# MK40D7 register map
File version: 1.6
Registers are 32-bit, read-write, reset 0x0 unless marked. A register's access mark holds for its fields unless they carry their own. Offsets are from the block's base; [hi:lo] are bit positions; {n}, {i} and the like mark numbered series.

## USB0 — Universal Serial Bus, OTG Capable Controller
Base 0x40072000; register names take the prefix USB0_
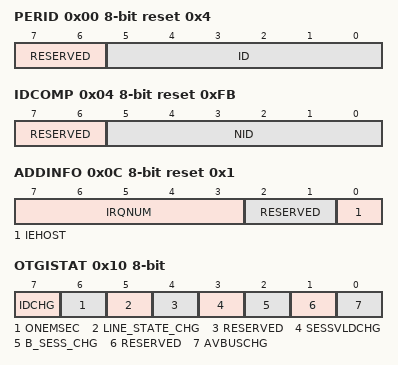
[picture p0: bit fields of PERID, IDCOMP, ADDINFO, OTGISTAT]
0x00 PERID 8-bit ro reset 0x4 — Peripheral ID Register
  [7:6] RESERVED
  [5:0] ID — Peripheral identification bits
0x04 IDCOMP 8-bit ro reset 0xFB — Peripheral ID Complement Register
  [7:6] RESERVED, [5:0] NID
0x08 REV 8-bit ro reset 0x33 — Peripheral Revision Register
  [7:0] REV — Revision
0x0C ADDINFO 8-bit ro reset 0x1 — Peripheral Additional Info Register
  [7:3] IRQNUM — Assigned Interrupt Request Number
  [2:1] RESERVED
  [0] IEHOST
0x10 OTGISTAT 8-bit access per field — OTG Interrupt Status Register
  [7] IDCHG rw, [6] ONEMSEC rw, [5] LINE_STATE_CHG rw, [4] RESERVED ro, [3] SESSVLDCHG rw, [2] B_SESS_CHG rw, [1] RESERVED ro, [0] AVBUSCHG rw
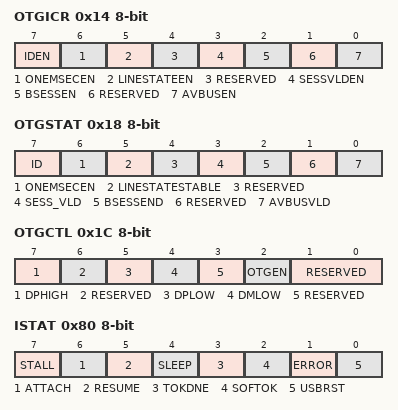
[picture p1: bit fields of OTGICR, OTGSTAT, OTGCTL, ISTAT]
0x14 OTGICR 8-bit access per field — OTG Interrupt Control Register
  [7] IDEN rw — ID interrupt enable
    0=The ID interrupt is disabled; 1=The ID interrupt is enabled
  [6] ONEMSECEN rw — 1 millisecond interrupt enable
    0=The 1msec timer interrupt is disabled; 1=The 1msec timer interrupt is enabled
  [5] LINESTATEEN rw — Line State change interrupt enable
    0=The LINE_STAT_CHG interrupt is disabled; 1=The LINE_STAT_CHG interrupt is enabled
  [4] RESERVED ro
  [3] SESSVLDEN rw — Session valid interrupt enable
    0=The SESSVLDCHG interrupt is disabled; 1=The SESSVLDCHG interrupt is enabled
  [2] BSESSEN rw — B Session END interrupt enable
    0=The B_SESS_CHG interrupt is disabled; 1=The B_SESS_CHG interrupt is enabled
  [1] RESERVED ro
  [0] AVBUSEN rw — A VBUS Valid interrupt enable
    0=The AVBUSCHG interrupt is disabled; 1=The AVBUSCHG interrupt is enabled
0x18 OTGSTAT 8-bit access per field — OTG Status Register
  [7] ID rw
    0=Indicates a Type A cable has been plugged into the USB connector; 1=Indicates no cable is attached or a Type B cable has been plugged into the USB connector
  [6] ONEMSECEN rw
  [5] LINESTATESTABLE rw
    0=The LINE_STAT_CHG bit is not yet stable; 1=The LINE_STAT_CHG bit has been debounced and is stable
  [4] RESERVED ro
  [3] SESS_VLD rw — Session valid
    0=The VBUS voltage is below the B session Valid threshold; 1=The VBUS voltage is above the B session Valid threshold
  [2] BSESSEND rw — B Session END
    0=The VBUS voltage is above the B session End threshold; 1=The VBUS voltage is below the B session End threshold
  [1] RESERVED ro
  [0] AVBUSVLD rw — A VBUS Valid
    0=The VBUS voltage is below the A VBUS Valid threshold; 1=The VBUS voltage is above the A VBUS Valid threshold
0x1C OTGCTL 8-bit access per field — OTG Control Register
  [7] DPHIGH rw — D+ Data Line pullup resistor enable
    0=D+ pullup resistor is not enabled; 1=D+ pullup resistor is enabled
  [6] RESERVED ro
  [5] DPLOW rw — D+ Data Line pull-down resistor enable
    0=D+ pulldown resistor is not enabled; 1=D+ pulldown resistor is enabled
  [4] DMLOW rw — D- Data Line pull-down resistor enable
    0=D- pulldown resistor is not enabled; 1=D- pulldown resistor is enabled
  [3] RESERVED ro
  [2] OTGEN rw — On-The-Go pullup/pulldown resistor enable
    0=If USB_EN is set and HOST_MODE is clear in the Control Register (CTL), then the D+ Data Line pull-up resistors are enabled. If HOST_MODE is set the D+ and D- Data Line pull-down resistors are engaged.; 1=The pull-up and pull-down controls in this register are used
  [1:0] RESERVED ro
0x80 ISTAT 8-bit — Interrupt Status Register
  [7] STALL — Stall Interrupt
  [6] ATTACH — Attach Interrupt
  [5] RESUME
  [4] SLEEP
  [3] TOKDNE
  [2] SOFTOK
  [1] ERROR
  [0] USBRST
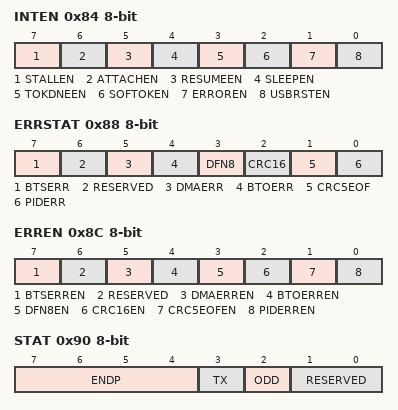
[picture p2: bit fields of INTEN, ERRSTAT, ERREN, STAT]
0x84 INTEN 8-bit — Interrupt Enable Register
  [7] STALLEN — STALL Interrupt Enable
    0=The STALL interrupt is not enabled; 1=The STALL interrupt is enabled
  [6] ATTACHEN — ATTACH Interrupt Enable
    0=The ATTACH interrupt is not enabled; 1=The ATTACH interrupt is enabled
  [5] RESUMEEN — RESUME Interrupt Enable
    0=The RESUME interrupt is not enabled; 1=The RESUME interrupt is enabled
  [4] SLEEPEN — SLEEP Interrupt Enable
    0=The SLEEP interrupt is not enabled; 1=The SLEEP interrupt is enabled
  [3] TOKDNEEN — TOKDNE Interrupt Enable
    0=The TOKDNE interrupt is not enabled; 1=The TOKDNE interrupt is enabled
  [2] SOFTOKEN — SOFTOK Interrupt Enable
    0=The SOFTOK interrupt is not enabled; 1=The SOFTOK interrupt is enabled
  [1] ERROREN — ERROR Interrupt Enable
    0=The ERROR interrupt is not enabled; 1=The ERROR interrupt is enabled
  [0] USBRSTEN — USBRST Interrupt Enable
    0=The USBRST interrupt is not enabled; 1=The USBRST interrupt is enabled
0x88 ERRSTAT 8-bit access per field — Error Interrupt Status Register
  [7] BTSERR rw, [6] RESERVED ro, [5] DMAERR rw, [4] BTOERR rw, [3] DFN8 rw, [2] CRC16 rw, [1] CRC5EOF rw, [0] PIDERR rw
0x8C ERREN 8-bit access per field — Error Interrupt Enable Register
  [7] BTSERREN rw — BTSERR Interrupt Enable
    0=The BTSERR interrupt is not enabled; 1=The BTSERR interrupt is enabled
  [6] RESERVED ro
  [5] DMAERREN rw — DMAERR Interrupt Enable
    0=The DMAERR interrupt is not enabled; 1=The DMAERR interrupt is enabled
  [4] BTOERREN rw — BTOERR Interrupt Enable
    0=The BTOERR interrupt is not enabled; 1=The BTOERR interrupt is enabled
  [3] DFN8EN rw — DFN8 Interrupt Enable
    0=The DFN8 interrupt is not enabled; 1=The DFN8 interrupt is enabled
  [2] CRC16EN rw — CRC16 Interrupt Enable
    0=The CRC16 interrupt is not enabled; 1=The CRC16 interrupt is enabled
  [1] CRC5EOFEN rw — CRC5/EOF Interrupt Enable
    0=The CRC5/EOF interrupt is not enabled; 1=The CRC5/EOF interrupt is enabled
  [0] PIDERREN rw — PIDERR Interrupt Enable
    0=The PIDERR interrupt is not enabled; 1=The PIDERR interrupt is enabled
0x90 STAT 8-bit ro — Status Register
  [7:4] ENDP
  [3] TX — Transmit Indicator
    0=The most recent transaction was a Receive operation; 1=The most recent transaction was a Transmit operation
  [2] ODD
  [1:0] RESERVED
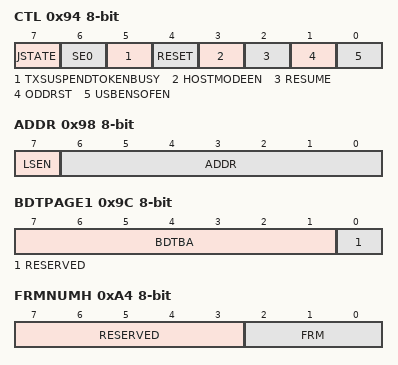
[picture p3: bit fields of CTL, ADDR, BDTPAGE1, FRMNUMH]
0x94 CTL 8-bit — Control Register
  [7] JSTATE — Live USB differential receiver JSTATE signal
  [6] SE0 — Live USB Single Ended Zero signal
  [5] TXSUSPENDTOKENBUSY
  [4] RESET
  [3] HOSTMODEEN
  [2] RESUME
  [1] ODDRST
  [0] USBENSOFEN — USB Enable
    0=The USB Module is disabled; 1=The USB Module is enabled
0x98 ADDR 8-bit — Address Register
  [7] LSEN — Low Speed Enable bit
  [6:0] ADDR — USB address
0x9C BDTPAGE1 8-bit access per field — BDT Page Register 1
  [7:1] BDTBA rw, [0] RESERVED ro
0xA0 FRMNUML 8-bit — Frame Number Register Low
  [7:0] FRM
0xA4 FRMNUMH 8-bit access per field — Frame Number Register High
  [7:3] RESERVED ro, [2:0] FRM rw
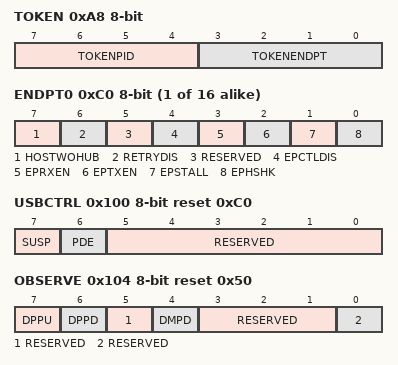
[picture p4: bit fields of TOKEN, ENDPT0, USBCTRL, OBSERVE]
0xA8 TOKEN 8-bit
  [7:4] TOKENPID
    1=OUT Token. USB Module performs an OUT (TX) transaction.; 9=IN Token. USB Module performs an In (RX) transaction.; 13=SETUP Token. USB Module performs a SETUP (TX) transaction
  [3:0] TOKENENDPT
0xAC SOFTHLD 8-bit — SOF Threshold Register
  [7:0] CNT
0xB0 BDTPAGE2 8-bit — BDT Page Register 2
  [7:0] BDTBA
0xB4 BDTPAGE3 8-bit — BDT Page Register 3
  [7:0] BDTBA
{0xC0+4i} ENDPT{i} (i=0..15) 8-bit access per field — Endpoint Control Register
  [7] HOSTWOHUB rw, [6] RETRYDIS rw, [5] RESERVED ro, [4] EPCTLDIS rw, [3] EPRXEN rw, [2] EPTXEN rw, [1] EPSTALL rw, [0] EPHSHK rw
0x100 USBCTRL 8-bit access per field reset 0xC0 — USB Control Register
  [7] SUSP rw
    0=USB transceiver is not in suspend state; 1=USB transceiver is in suspend state
  [6] PDE rw
    0=Weak pulldowns are disabled on D+ and D-; 1=Weak pulldowns are enabled on D+ and D-
  [5:0] RESERVED ro
0x104 OBSERVE 8-bit ro reset 0x50 — USB OTG Observe Register
  [7] DPPU
    0=D+ pullup disabled; 1=D+ pullup enabled
  [6] DPPD
    0=D+ pulldown disabled; 1=D+ pulldown enabled
  [5] RESERVED
  [4] DMPD
    0=D- pulldown disabled; 1=D- pulldown enabled
  [3:1] RESERVED
  [0] RESERVED
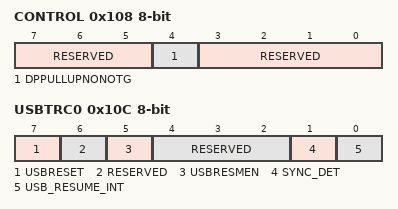
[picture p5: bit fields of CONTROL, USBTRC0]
0x108 CONTROL 8-bit access per field — USB OTG Control Register
  [7:5] RESERVED ro
  [4] DPPULLUPNONOTG rw
    0=DP Pull up in non-OTG device mode is not enabled; 1=DP Pull up in non-OTG device mode is enabled
  [3:0] RESERVED ro
0x10C USBTRC0 8-bit access per field — USB Transceiver Control Register 0
  [7] USBRESET wo
    0=Normal USB module operation; 1=Returns the USB module to its reset state
  [6] RESERVED ro
  [5] USBRESMEN rw — Asynchronous Resume Interrupt Enable
    0=USB asynchronous wakeup from suspend mode disabled; 1=USB asynchronous wakeup from suspend mode enabled. The asynchronous resume interrupt differs from the synchronous resume interrupt in that it asynchronously detects K-state using the unfiltered state of the D+ and D- pins. This interupt should only be enabled when the Transceiver is suspended.
  [4:2] RESERVED ro
  [1] SYNC_DET ro — Synchronous USB Interrupt Detect
    0=Synchronous interrupt has not been detected; 1=Synchronous interrupt has been detected
  [0] USB_RESUME_INT ro — USB Asynchronous Interrupt
    0=No interrupt was generated; 1=Interrupt was generated because of the USB asynchronous interrupt
0x114 USBFRMADJUST 8-bit — Frame Adjust Register
  [7:0] ADJ — Frame Adjustment
